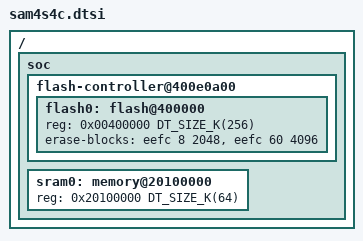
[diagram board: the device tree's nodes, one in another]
/*
 * Copyright (c) 2018 Vincent van der Locht
 *
 * SPDX-License-Identifier: Apache-2.0
 */

#include <mem.h>
#include <atmel/sam4s.dtsi>

/ {
	soc {
		flash-controller@400e0a00 {
			flash0: flash@400000 {
				reg = <0x00400000 DT_SIZE_K(256)>;
				erase-blocks = <&eefc 8 2048>, <&eefc 60 4096>;
			};
		};

		sram0: memory@20100000 {
			reg = <0x20100000 DT_SIZE_K(64)>;
		};
	};
};
